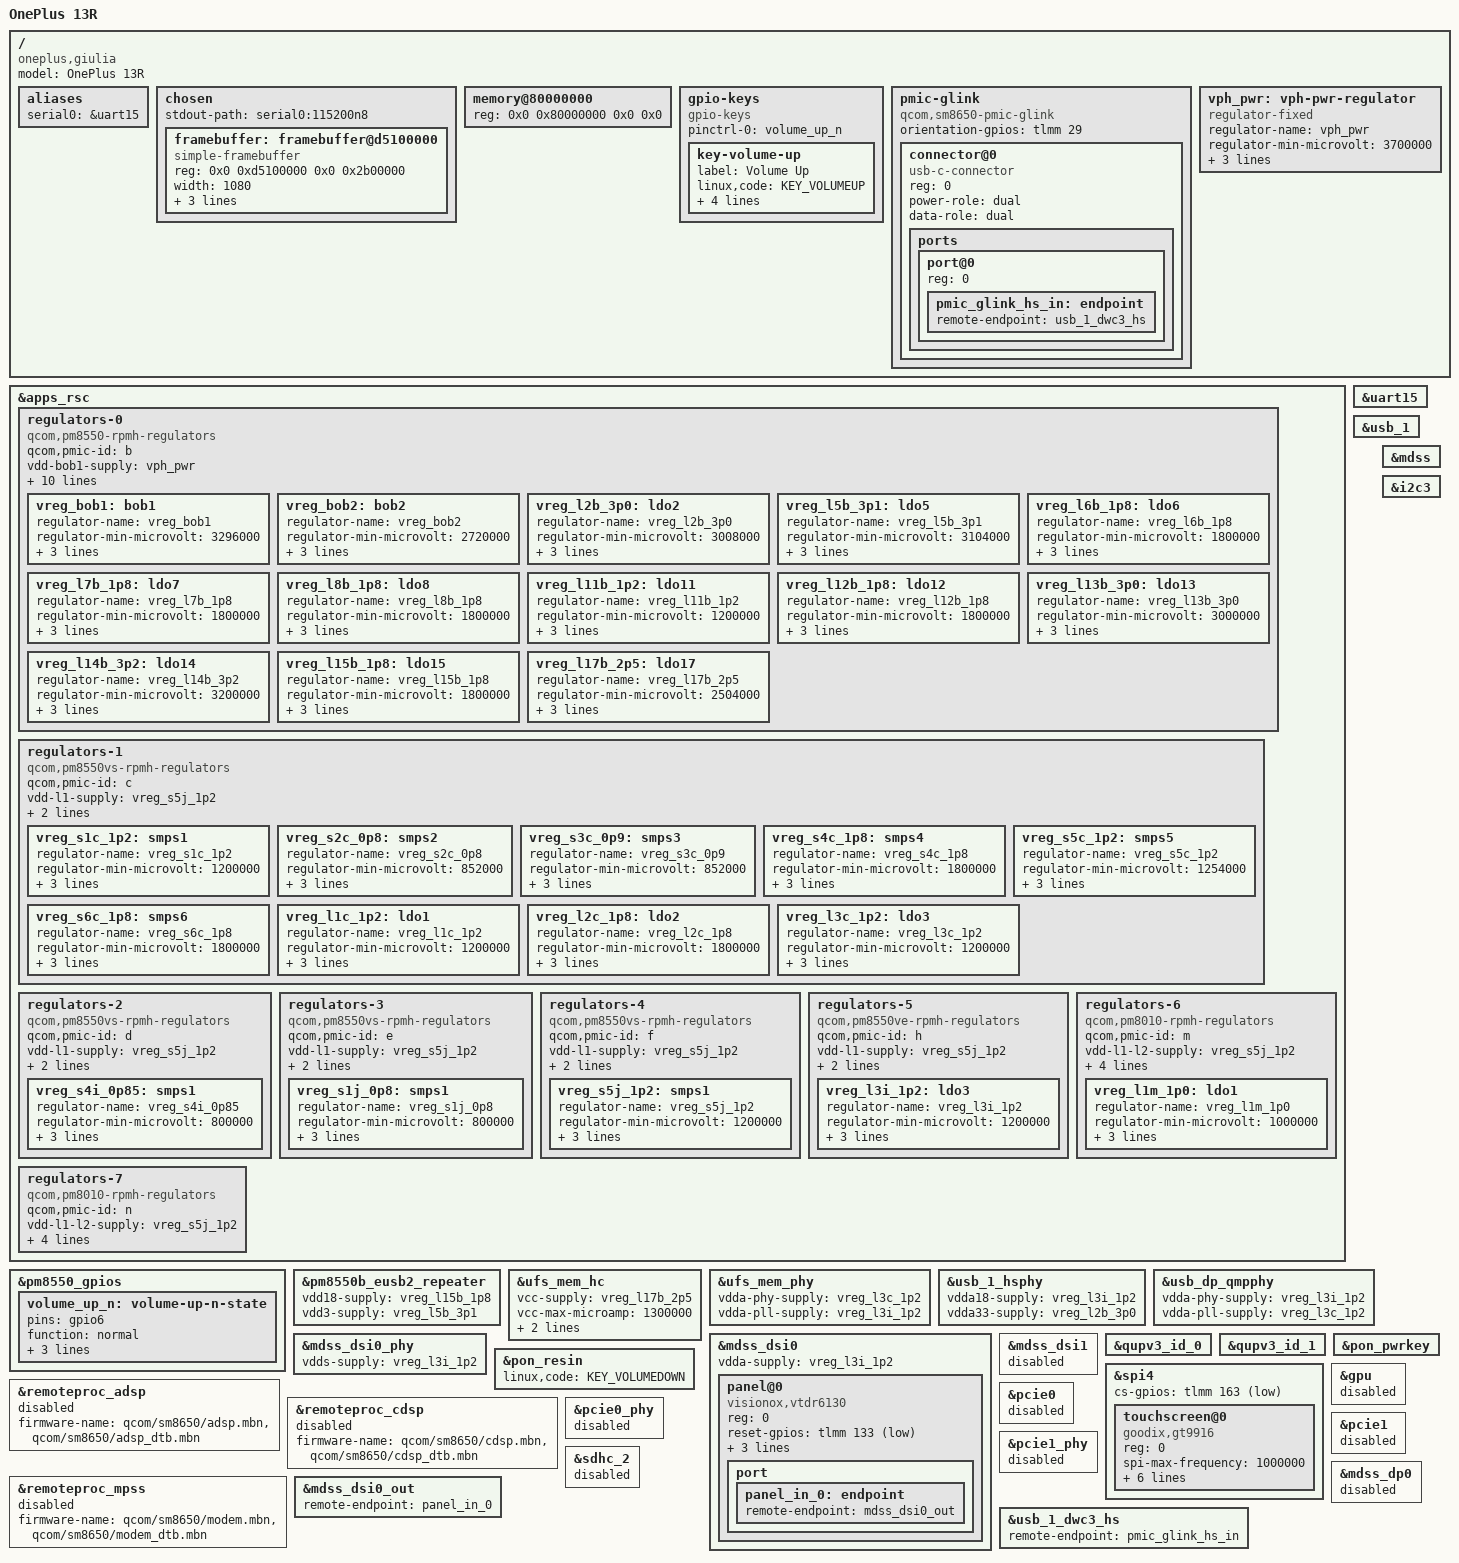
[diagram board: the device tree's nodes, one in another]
/dts-v1/;

#include "sm8650.dtsi"   /* This pulls in the CPU/SoC logic */
#include <dt-bindings/input/input.h>
#include <dt-bindings/gpio/gpio.h>
#include <dt-bindings/leds/common.h>
#include <dt-bindings/regulator/qcom,rpmh-regulator.h>

/* Include your PMICs here */
#include "pm8010.dtsi"
#include "pm8550.dtsi"
#include "pm8550b.dtsi"
#define PMK8550VE_SID 8
#include "pm8550ve.dtsi"
#include "pm8550vs.dtsi"
#include "pmk8550.dtsi"
#include "pmr735d_a.dtsi"

/ {
	model = "OnePlus 13R";
	compatible = "oneplus,giulia", "qcom,sm8650";

	aliases {
		serial0 = &uart15;
	};
	chosen {
		stdout-path = "serial0:115200n8";

		#address-cells = <2>;
		#size-cells = <2>;

	framebuffer: framebuffer@d5100000 {
		compatible = "simple-framebuffer";
		reg = <0x0 0xd5100000 0x0 0x2b00000>;
		width = <1080>;
		height = <2400>;
		stride = <4320>; /* 1080 width * 4 bytes per pixel */
		format = "a8r8g8b8";
	};
};

	memory@80000000 {
		device_type = "memory";

		/*
		 * Placeholder only.
		 * Qualcomm ABL should patch this with the real usable RAM map
		 * before U-Boot consumes the DTB.
		 */
		reg = <0x0 0x80000000 0x0 0x0>;
	};

	gpio-keys {
		compatible = "gpio-keys";

		pinctrl-0 = <&volume_up_n>;
		pinctrl-names = "default";

		key-volume-up {
			label = "Volume Up";
			linux,code = <KEY_VOLUMEUP>;
			gpios = <&pm8550_gpios 6 GPIO_ACTIVE_LOW>;
			debounce-interval = <15>;
			linux,can-disable;
			wakeup-source;
		};
	};

	/* QRD has a full pmic-glink with redriver/sbu mux.
	 * Giulia uses a simpler direct connection. Remove
	 * redriver and wcd_usbss references, keep basic connector.
	 */
	pmic-glink {
		compatible = "qcom,sm8650-pmic-glink",
			     "qcom,sm8550-pmic-glink",
			     "qcom,pmic-glink";
		#address-cells = <1>;
		#size-cells = <0>;
		orientation-gpios = <&tlmm 29 GPIO_ACTIVE_HIGH>;

		connector@0 {
			compatible = "usb-c-connector";
			reg = <0>;
			power-role = "dual";
			data-role = "dual";

			ports {
				#address-cells = <1>;
				#size-cells = <0>;

				port@0 {
					reg = <0>;
					pmic_glink_hs_in: endpoint {
						remote-endpoint = <&usb_1_dwc3_hs>;
					};
				};
			};
		};
	};

	vph_pwr: vph-pwr-regulator {
		compatible = "regulator-fixed";
		regulator-name = "vph_pwr";
		regulator-min-microvolt = <3700000>;
		regulator-max-microvolt = <3700000>;
		regulator-always-on;
		regulator-boot-on;
	};
};

/* ================================================================ */
/* RPMH REGULATORS — from QRD, kept as-is. Fix wrong voltages later */
/* ================================================================ */
&apps_rsc {
	regulators-0 {
		compatible = "qcom,pm8550-rpmh-regulators";
		qcom,pmic-id = "b";

		vdd-bob1-supply = <&vph_pwr>;
		vdd-bob2-supply = <&vph_pwr>;
		vdd-l2-l13-l14-supply = <&vreg_bob1>;
		vdd-l3-supply = <&vreg_s1c_1p2>;
		vdd-l5-l16-supply = <&vreg_bob1>;
		vdd-l6-l7-supply = <&vreg_bob1>;
		vdd-l8-l9-supply = <&vreg_bob1>;
		vdd-l11-supply = <&vreg_s1c_1p2>;
		vdd-l12-supply = <&vreg_s6c_1p8>;
		vdd-l15-supply = <&vreg_s6c_1p8>;
		vdd-l17-supply = <&vreg_bob2>;

		vreg_bob1: bob1 {
			regulator-name = "vreg_bob1";
			regulator-min-microvolt = <3296000>;
			regulator-max-microvolt = <3960000>;
			regulator-initial-mode = <RPMH_REGULATOR_MODE_HPM>;
		};

		vreg_bob2: bob2 {
			regulator-name = "vreg_bob2";
			regulator-min-microvolt = <2720000>;
			regulator-max-microvolt = <3008000>;
			regulator-initial-mode = <RPMH_REGULATOR_MODE_HPM>;
		};

		vreg_l2b_3p0: ldo2 {
			regulator-name = "vreg_l2b_3p0";
			regulator-min-microvolt = <3008000>;
			regulator-max-microvolt = <3008000>;
			regulator-initial-mode = <RPMH_REGULATOR_MODE_HPM>;
		};

		vreg_l5b_3p1: ldo5 {
			regulator-name = "vreg_l5b_3p1";
			regulator-min-microvolt = <3104000>;
			regulator-max-microvolt = <3104000>;
			regulator-initial-mode = <RPMH_REGULATOR_MODE_HPM>;
		};

		vreg_l6b_1p8: ldo6 {
			regulator-name = "vreg_l6b_1p8";
			regulator-min-microvolt = <1800000>;
			regulator-max-microvolt = <3008000>;
			regulator-initial-mode = <RPMH_REGULATOR_MODE_HPM>;
		};

		vreg_l7b_1p8: ldo7 {
			regulator-name = "vreg_l7b_1p8";
			regulator-min-microvolt = <1800000>;
			regulator-max-microvolt = <3008000>;
			regulator-initial-mode = <RPMH_REGULATOR_MODE_HPM>;
		};

		vreg_l8b_1p8: ldo8 {
			regulator-name = "vreg_l8b_1p8";
			regulator-min-microvolt = <1800000>;
			regulator-max-microvolt = <3008000>;
			regulator-initial-mode = <RPMH_REGULATOR_MODE_HPM>;
		};

		vreg_l11b_1p2: ldo11 {
			regulator-name = "vreg_l11b_1p2";
			regulator-min-microvolt = <1200000>;
			regulator-max-microvolt = <1504000>;
			regulator-initial-mode = <RPMH_REGULATOR_MODE_HPM>;
		};

		vreg_l12b_1p8: ldo12 {
			regulator-name = "vreg_l12b_1p8";
			regulator-min-microvolt = <1800000>;
			regulator-max-microvolt = <1800000>;
			regulator-initial-mode = <RPMH_REGULATOR_MODE_HPM>;
		};

		vreg_l13b_3p0: ldo13 {
			regulator-name = "vreg_l13b_3p0";
			regulator-min-microvolt = <3000000>;
			regulator-max-microvolt = <3000000>;
			regulator-initial-mode = <RPMH_REGULATOR_MODE_HPM>;
		};

		vreg_l14b_3p2: ldo14 {
			regulator-name = "vreg_l14b_3p2";
			regulator-min-microvolt = <3200000>;
			regulator-max-microvolt = <3200000>;
			regulator-initial-mode = <RPMH_REGULATOR_MODE_HPM>;
		};

		vreg_l15b_1p8: ldo15 {
			regulator-name = "vreg_l15b_1p8";
			regulator-min-microvolt = <1800000>;
			regulator-max-microvolt = <1800000>;
			regulator-initial-mode = <RPMH_REGULATOR_MODE_HPM>;
		};

		vreg_l17b_2p5: ldo17 {
			regulator-name = "vreg_l17b_2p5";
			regulator-min-microvolt = <2504000>;
			regulator-max-microvolt = <2504000>;
			regulator-initial-mode = <RPMH_REGULATOR_MODE_HPM>;
		};
	};

	regulators-1 {
		compatible = "qcom,pm8550vs-rpmh-regulators";
		qcom,pmic-id = "c";

		vdd-l1-supply = <&vreg_s5j_1p2>;
		vdd-l2-supply = <&vreg_s1j_0p8>;
		vdd-l3-supply = <&vreg_s5j_1p2>;

		vreg_s1c_1p2: smps1 {
			regulator-name = "vreg_s1c_1p2";
			regulator-min-microvolt = <1200000>;
			regulator-max-microvolt = <1300000>;
			regulator-initial-mode = <RPMH_REGULATOR_MODE_HPM>;
		};

		vreg_s2c_0p8: smps2 {
			regulator-name = "vreg_s2c_0p8";
			regulator-min-microvolt = <852000>;
			regulator-max-microvolt = <1104000>;
			regulator-initial-mode = <RPMH_REGULATOR_MODE_HPM>;
		};

		vreg_s3c_0p9: smps3 {
			regulator-name = "vreg_s3c_0p9";
			regulator-min-microvolt = <852000>;
			regulator-max-microvolt = <1104000>;
			regulator-initial-mode = <RPMH_REGULATOR_MODE_HPM>;
		};

		vreg_s4c_1p8: smps4 {
			regulator-name = "vreg_s4c_1p8";
			regulator-min-microvolt = <1800000>;
			regulator-max-microvolt = <1800000>;
			regulator-initial-mode = <RPMH_REGULATOR_MODE_HPM>;
		};

		vreg_s5c_1p2: smps5 {
			regulator-name = "vreg_s5c_1p2";
			regulator-min-microvolt = <1254000>;
			regulator-max-microvolt = <1360000>;
			regulator-initial-mode = <RPMH_REGULATOR_MODE_HPM>;
		};

		vreg_s6c_1p8: smps6 {
			regulator-name = "vreg_s6c_1p8";
			regulator-min-microvolt = <1800000>;
			regulator-max-microvolt = <1950000>;
			regulator-initial-mode = <RPMH_REGULATOR_MODE_HPM>;
		};

		vreg_l1c_1p2: ldo1 {
			regulator-name = "vreg_l1c_1p2";
			regulator-min-microvolt = <1200000>;
			regulator-max-microvolt = <1200000>;
			regulator-initial-mode = <RPMH_REGULATOR_MODE_HPM>;
		};

		vreg_l2c_1p8: ldo2 {
			regulator-name = "vreg_l2c_1p8";
			regulator-min-microvolt = <1800000>;
			regulator-max-microvolt = <1800000>;
			regulator-initial-mode = <RPMH_REGULATOR_MODE_HPM>;
		};

		vreg_l3c_1p2: ldo3 {
			regulator-name = "vreg_l3c_1p2";
			regulator-min-microvolt = <1200000>;
			regulator-max-microvolt = <1200000>;
			regulator-initial-mode = <RPMH_REGULATOR_MODE_HPM>;
		};
	};

	regulators-2 {
		compatible = "qcom,pm8550vs-rpmh-regulators";
		qcom,pmic-id = "d";

		vdd-l1-supply = <&vreg_s5j_1p2>;
		vdd-l2-supply = <&vreg_s1j_0p8>;
		vdd-l3-supply = <&vreg_s5j_1p2>;

		vreg_s4i_0p85: smps1 {
			regulator-name = "vreg_s4i_0p85";
			regulator-min-microvolt = <800000>;
			regulator-max-microvolt = <1000000>;
			regulator-initial-mode = <RPMH_REGULATOR_MODE_HPM>;
		};
	};

	regulators-3 {
		compatible = "qcom,pm8550vs-rpmh-regulators";
		qcom,pmic-id = "e";

		vdd-l1-supply = <&vreg_s5j_1p2>;
		vdd-l2-supply = <&vreg_s1j_0p8>;
		vdd-l3-supply = <&vreg_s5j_1p2>;

		vreg_s1j_0p8: smps1 {
			regulator-name = "vreg_s1j_0p8";
			regulator-min-microvolt = <800000>;
			regulator-max-microvolt = <1000000>;
			regulator-initial-mode = <RPMH_REGULATOR_MODE_HPM>;
		};
	};

	regulators-4 {
		compatible = "qcom,pm8550vs-rpmh-regulators";
		qcom,pmic-id = "f";

		vdd-l1-supply = <&vreg_s5j_1p2>;
		vdd-l2-supply = <&vreg_s1j_0p8>;
		vdd-l3-supply = <&vreg_s5j_1p2>;

		vreg_s5j_1p2: smps1 {
			regulator-name = "vreg_s5j_1p2";
			regulator-min-microvolt = <1200000>;
			regulator-max-microvolt = <1300000>;
			regulator-initial-mode = <RPMH_REGULATOR_MODE_HPM>;
		};
	};

	regulators-5 {
		compatible = "qcom,pm8550ve-rpmh-regulators";
		qcom,pmic-id = "h";

		vdd-l1-supply = <&vreg_s5j_1p2>;
		vdd-l2-supply = <&vreg_s1j_0p8>;
		vdd-l3-supply = <&vreg_s5j_1p2>;

		vreg_l3i_1p2: ldo3 {
			regulator-name = "vreg_l3i_1p2";
			regulator-min-microvolt = <1200000>;
			regulator-max-microvolt = <1200000>;
			regulator-initial-mode = <RPMH_REGULATOR_MODE_HPM>;
		};
	};

	regulators-6 {
		compatible = "qcom,pm8010-rpmh-regulators";
		qcom,pmic-id = "m";

		vdd-l1-l2-supply = <&vreg_s5j_1p2>;
		vdd-l3-l4-supply = <&vreg_bob2>;
		vdd-l5-supply = <&vreg_s6c_1p8>;
		vdd-l6-supply = <&vreg_bob1>;
		vdd-l7-supply = <&vreg_bob2>;

		vreg_l1m_1p0: ldo1 {
			regulator-name = "vreg_l1m_1p0";
			regulator-min-microvolt = <1000000>;
			regulator-max-microvolt = <1100000>;
			regulator-initial-mode = <RPMH_REGULATOR_MODE_HPM>;
		};
	};

	regulators-7 {
		compatible = "qcom,pm8010-rpmh-regulators";
		qcom,pmic-id = "n";

		vdd-l1-l2-supply = <&vreg_s5j_1p2>;
		vdd-l3-l4-supply = <&vreg_bob2>;
		vdd-l5-supply = <&vreg_s6c_1p8>;
		vdd-l6-supply = <&vreg_bob1>;
		vdd-l7-supply = <&vreg_bob2>;
	};
};

/* ================================================================ */
/* PMIC GPIOs                                                        */
/* ================================================================ */
&pm8550_gpios {
	volume_up_n: volume-up-n-state {
		pins = "gpio6";
		function = "normal";
		bias-pull-up;
		input-enable;
		power-source = <1>;
	};
};

&pm8550b_eusb2_repeater {
	vdd18-supply = <&vreg_l15b_1p8>;
	vdd3-supply = <&vreg_l5b_3p1>;
};

/* ================================================================ */
/* UART debug console                                                */
/* ================================================================ */
&uart15 {
	status = "okay";
};

/* ================================================================ */
/* UFS                                                               */
/* ================================================================ */
&ufs_mem_hc {
	vcc-supply = <&vreg_l17b_2p5>;
	vcc-max-microamp = <1300000>;
	vccq-supply = <&vreg_l6b_1p8>;
	vccq-max-microamp = <1200000>;
	status = "okay";
};

&ufs_mem_phy {
	vdda-phy-supply = <&vreg_l3c_1p2>;
	vdda-pll-supply = <&vreg_l3i_1p2>;
	status = "okay";
};

/* ================================================================ */
/* USB                                                               */
/* ================================================================ */
&usb_1 {
	status = "okay";
};

&usb_1_hsphy {
	vdda18-supply = <&vreg_l3i_1p2>;
	vdda33-supply = <&vreg_l2b_3p0>;
	status = "okay";
};

&usb_dp_qmpphy {
	vdda-phy-supply = <&vreg_l3i_1p2>;
	vdda-pll-supply = <&vreg_l3c_1p2>;
	status = "okay";
};

/* ================================================================ */
/* Display                                                           */
/* ================================================================ */
&mdss {
	status = "okay";
};

&mdss_dsi0 {
	vdda-supply = <&vreg_l3i_1p2>;
	status = "okay";

	panel@0 {
		compatible = "visionox,vtdr6130";
		reg = <0>;

		reset-gpios = <&tlmm 133 GPIO_ACTIVE_LOW>;

		vddio-supply = <&vreg_l12b_1p8>;
		vci-supply = <&vreg_l13b_3p0>;
		vdd-supply = <&vreg_l13b_3p0>;

		port {
			panel_in_0: endpoint {
				remote-endpoint = <&mdss_dsi0_out>;
			};
		};
	};
};

&mdss_dsi0_phy {
	vdds-supply = <&vreg_l3i_1p2>;
	status = "okay";
};

&mdss_dsi1 {
	status = "disabled";
};

/* ================================================================ */
/* QUP buses                                                         */
/* ================================================================ */
&qupv3_id_0 {
	status = "okay";
};

&qupv3_id_1 {
	status = "okay";
};

/* ================================================================ */
/* Touchscreen (SPI4)                                                */
/* ================================================================ */
&spi4 {
	status = "okay";
	cs-gpios = <&tlmm 163 GPIO_ACTIVE_LOW>;

	touchscreen@0 {
		compatible = "goodix,gt9916";
		reg = <0>;
		spi-max-frequency = <1000000>;

		interrupt-parent = <&tlmm>;
		interrupts = <162 IRQ_TYPE_LEVEL_LOW>;

		reset-gpios = <&tlmm 161 GPIO_ACTIVE_LOW>;
		irq-gpios = <&tlmm 162 GPIO_ACTIVE_LOW>;

		avdd-supply = <&vreg_l14b_3p2>;
		iovdd-supply = <&vreg_l12b_1p8>;
	};
};

/* ================================================================ */
/* I2C3 — used for WCD audio codec                                  */
/* ================================================================ */
&i2c3 {
	status = "okay";
};

/* ================================================================ */
/* PMIC power/reset                                                  */
/* ================================================================ */
&pon_pwrkey {
	status = "okay";
};

&pon_resin {
	linux,code = <KEY_VOLUMEDOWN>;
	status = "okay";
};

/* ================================================================ */
/* Remote processors — firmware-name set, disabled for bringup       */
/* ================================================================ */
&remoteproc_adsp {
	firmware-name = "qcom/sm8650/adsp.mbn",
			"qcom/sm8650/adsp_dtb.mbn";
	status = "disabled";
};

&remoteproc_cdsp {
	firmware-name = "qcom/sm8650/cdsp.mbn",
			"qcom/sm8650/cdsp_dtb.mbn";
	status = "disabled";
};

&remoteproc_mpss {
	firmware-name = "qcom/sm8650/modem.mbn",
			"qcom/sm8650/modem_dtb.mbn";
	status = "disabled";
};

/* ================================================================ */
/* GPU — disabled for bringup                                       */
/* ================================================================ */
&gpu {
	status = "disabled";
};

/* ================================================================ */
/* PCIe — not used on 13R                                           */
/* ================================================================ */
&pcie0 { status = "disabled"; };
&pcie0_phy { status = "disabled"; };
&pcie1 { status = "disabled"; };
&pcie1_phy { status = "disabled"; };

/* ================================================================ */
/* SD Card — not present on 13R                                     */
/* ================================================================ */
&sdhc_2 { status = "disabled"; };

/* ================================================================ */
/* DisplayPort — disable (USB3+DP combo phy brings it in later)     */
/* ================================================================ */
&mdss_dp0 { status = "disabled"; };
&mdss_dsi0_out {
    remote-endpoint = <&panel_in_0>;
};
&usb_1_dwc3_hs {
	remote-endpoint = <&pmic_glink_hs_in>;
};
